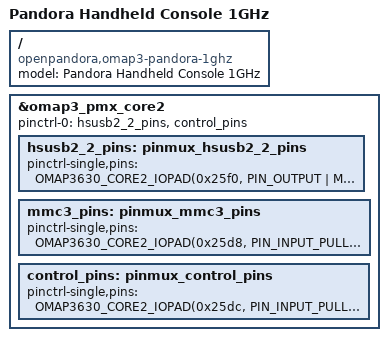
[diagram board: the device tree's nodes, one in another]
/*
 * Copyright (C) 2015
 *   Nikolaus Schaller <hns@goldelico.com>
 *
 * This program is free software; you can redistribute it and/or modify
 * it under the terms of the GNU General Public License version 2 as
 * published by the Free Software Foundation.
 */

/*
 * device tree for OpenPandora 1GHz with DM3730
 */

/dts-v1/;

#include "omap36xx.dtsi"
#include "omap3-pandora-common.dtsi"

/ {
	model = "Pandora Handheld Console 1GHz";

	compatible = "openpandora,omap3-pandora-1ghz", "ti,omap36xx", "ti,omap3";
};

&omap3_pmx_core2 {

	pinctrl-names = "default";
	pinctrl-0 = <
		&hsusb2_2_pins
		&control_pins
	>;

	hsusb2_2_pins: pinmux_hsusb2_2_pins {
		pinctrl-single,pins = <
			OMAP3630_CORE2_IOPAD(0x25f0, PIN_OUTPUT | MUX_MODE3)		/* etk_d10.hsusb2_clk */
			OMAP3630_CORE2_IOPAD(0x25f2, PIN_OUTPUT | MUX_MODE3)		/* etk_d11.hsusb2_stp */
			OMAP3630_CORE2_IOPAD(0x25f4, PIN_INPUT_PULLDOWN | MUX_MODE3)	/* etk_d12.hsusb2_dir */
			OMAP3630_CORE2_IOPAD(0x25f6, PIN_INPUT_PULLDOWN | MUX_MODE3)	/* etk_d13.hsusb2_nxt */
			OMAP3630_CORE2_IOPAD(0x25f8, PIN_INPUT_PULLDOWN | MUX_MODE3)	/* etk_d14.hsusb2_data0 */
			OMAP3630_CORE2_IOPAD(0x25fa, PIN_INPUT_PULLDOWN | MUX_MODE3)	/* etk_d15.hsusb2_data1 */
		>;
	};

	mmc3_pins: pinmux_mmc3_pins {
		pinctrl-single,pins = <
			OMAP3630_CORE2_IOPAD(0x25d8, PIN_INPUT_PULLUP | MUX_MODE2)	/* etk_clk.sdmmc3_clk */
			OMAP3630_CORE2_IOPAD(0x25da, PIN_INPUT_PULLUP | MUX_MODE2)	/* etk_ctl.sdmmc3_cmd */
			OMAP3630_CORE2_IOPAD(0x25e2, PIN_INPUT_PULLUP | MUX_MODE2)	/* etk_d3.sdmmc3_dat3 */
			OMAP3630_CORE2_IOPAD(0x25e4, PIN_INPUT_PULLUP | MUX_MODE2)	/* etk_d4.sdmmc3_dat0 */
			OMAP3630_CORE2_IOPAD(0x25e6, PIN_INPUT_PULLUP | MUX_MODE2)	/* etk_d5.sdmmc3_dat1 */
			OMAP3630_CORE2_IOPAD(0x25e8, PIN_INPUT_PULLUP | MUX_MODE2)	/* etk_d6.sdmmc3_dat2 */
		>;
	};

	control_pins: pinmux_control_pins {
		pinctrl-single,pins = <
			OMAP3630_CORE2_IOPAD(0x25dc, PIN_INPUT_PULLDOWN | MUX_MODE4)	/* etk_d0.gpio_14 =  HP_SHUTDOWN */
			OMAP3630_CORE2_IOPAD(0x25de, PIN_OUTPUT | MUX_MODE4)		/* etk_d1.gpio_15 =  BT_SHUTDOWN */
			OMAP3630_CORE2_IOPAD(0x25e0, PIN_OUTPUT | MUX_MODE4)		/* etk_d2.gpio_16 =  RESET_USB_HOST */
			OMAP3630_CORE2_IOPAD(0x25ea, PIN_INPUT | MUX_MODE4)		/* etk_d7.gpio_21 =  WIFI IRQ */
			OMAP3630_CORE2_IOPAD(0x25ec, PIN_OUTPUT | MUX_MODE4)		/* etk_d8.gpio_22 =  MSECURE */
			OMAP3630_CORE2_IOPAD(0x25ee, PIN_OUTPUT | MUX_MODE4)		/* etk_d9.gpio_23 =  WIFI_POWER */
			OMAP3_WKUP_IOPAD(0x2a54, PIN_INPUT | MUX_MODE4)   		/* reserved.gpio_127 = MMC2_WP */
			OMAP3_WKUP_IOPAD(0x2a56, PIN_INPUT | MUX_MODE4)   		/* reserved.gpio_126 = MMC1_WP */
			OMAP3_WKUP_IOPAD(0x2a58, PIN_OUTPUT | MUX_MODE4)   		/* reserved.gpio_128 = LED_MMC1 */
			OMAP3_WKUP_IOPAD(0x2a5a, PIN_OUTPUT | MUX_MODE4)   		/* reserved.gpio_129 = LED_MMC2 */

		>;
	};
};
